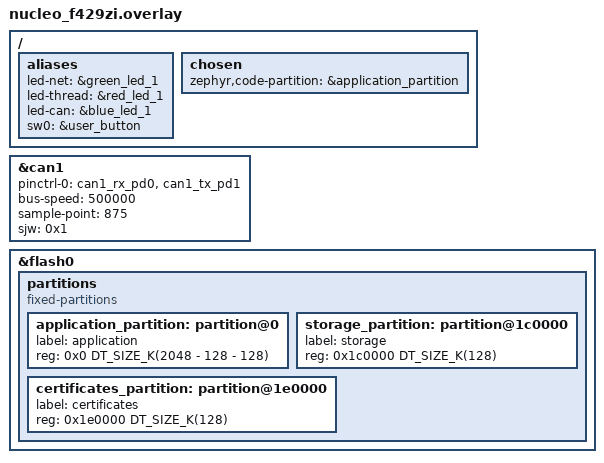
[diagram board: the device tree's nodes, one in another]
&can1 {
        status = "okay";
        pinctrl-0 = <&can1_rx_pd0 &can1_tx_pd1>;
        bus-speed = <500000>;

        sample-point = <875>; /* recommended value */
        sjw = <0x1>;
};

/ {
        aliases {
                led-net = &green_led_1;
                led-thread = &red_led_1;
                led-can = &blue_led_1;
                sw0 = &user_button;
        };
};

/* order matters */
/delete-node/ &boot_partition;
/delete-node/ &storage_partition;
/delete-node/ &slot0_partition;
/delete-node/ &slot1_partition;
/delete-node/ &scratch_partition;

&flash0 {
        // flash size is 0x200000
        partitions {
                compatible = "fixed-partitions";
                #address-cells = <0x1>;
                #size-cells = <0x1>;
                application_partition: partition@0 {
                        label = "application";
                        reg = <0x0 DT_SIZE_K(2048 - 128 - 128)>;
                };
                storage_partition: partition@1c0000 {
                        label = "storage";
                        reg = <0x1c0000 DT_SIZE_K(128)>;
                };
                certificates_partition: partition@1e0000 {
                        label = "certificates";
                        reg = <0x1e0000 DT_SIZE_K(128)>;
                };
        };
};

/* platformio doesn't show the correct FLASH usage 
 * when using overlay with custom partitions
 * 
 * Morever pio doesn't show CCM usage;
 */
/ {
        chosen {
                zephyr,code-partition = &application_partition;
        };
};



/* Second can bus isn't supported yet */
// &can2 {
//         status = "okay";
//         bus-speed = < 500000 >;
// };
